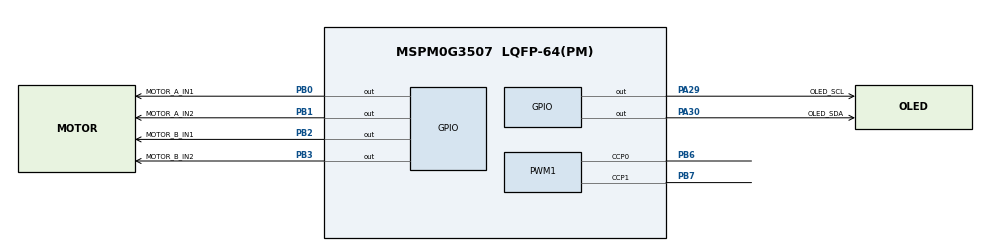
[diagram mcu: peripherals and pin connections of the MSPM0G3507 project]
/**
 * These arguments were used when this file was generated. They will be automatically applied on subsequent loads
 * via the GUI or CLI. Run CLI with '--help' for additional information on how to override these arguments.
 * @cliArgs --device "MSPM0G350X" --part "Default" --package "LQFP-64(PM)" --product "mspm0_sdk@2.10.00.04"
 * @v2CliArgs --device "MSPM0G3507" --package "LQFP-64(PM)" --product "mspm0_sdk@2.10.00.04"
 * @versions {"tool":"1.26.2+4477"}
 */

/**
 * Import the modules used in this configuration.
 */
const GPIO   = scripting.addModule("/ti/driverlib/GPIO", {}, false);
const GPIO1  = GPIO.addInstance();
const GPIO2  = GPIO.addInstance();
const PWM    = scripting.addModule("/ti/driverlib/PWM", {}, false);
const PWM1   = PWM.addInstance();
const SYSCTL = scripting.addModule("/ti/driverlib/SYSCTL");

/**
 * Write custom configuration values to the imported modules.
 */
const divider9       = system.clockTree["UDIV"];
divider9.divideValue = 2;

const multiplier2         = system.clockTree["PLL_QDIV"];
multiplier2.multiplyValue = 4;

const mux4       = system.clockTree["EXHFMUX"];
mux4.inputSelect = "EXHFMUX_XTAL";

const mux8       = system.clockTree["HSCLKMUX"];
mux8.inputSelect = "HSCLKMUX_SYSPLL0";

const mux12       = system.clockTree["SYSPLLMUX"];
mux12.inputSelect = "zSYSPLLMUX_HFCLK";

const pinFunction4       = system.clockTree["HFXT"];
pinFunction4.inputFreq   = 40;
pinFunction4.enable      = true;
pinFunction4.HFXTStartup = 128;

GPIO1.$name                         = "OLED";
GPIO1.associatedPins.create(2);
GPIO1.associatedPins[0].$name       = "OLED_SCL";
GPIO1.associatedPins[0].pin.$assign = "PA29";
GPIO1.associatedPins[1].$name       = "OLED_SDA";
GPIO1.associatedPins[1].pin.$assign = "PA30";

const Board = scripting.addModule("/ti/driverlib/Board", {}, false);

GPIO2.$name                         = "MOTOR_DIR";
GPIO2.associatedPins.create(4);
GPIO2.associatedPins[0].$name       = "MOTOR_A_IN1";
GPIO2.associatedPins[0].pin.$assign = "PB0";
GPIO2.associatedPins[1].$name       = "MOTOR_A_IN2";
GPIO2.associatedPins[1].pin.$assign = "PB1";
GPIO2.associatedPins[2].$name       = "MOTOR_B_IN1";
GPIO2.associatedPins[2].pin.$assign = "PB2";
GPIO2.associatedPins[3].$name       = "MOTOR_B_IN2";
GPIO2.associatedPins[3].pin.$assign = "PB3";

PWM1.$name                      = "PWM_0";
PWM1.timerCount                 = 4000;
PWM1.PWM_CHANNEL_0.$name        = "ti_driverlib_pwm_PWMTimerCC0";
PWM1.ccp0PinConfig.$name        = "ti_driverlib_gpio_GPIOPinGeneric0";
PWM1.peripheral.ccp0Pin.$assign = "PB6";
PWM1.peripheral.ccp1Pin.$assign = "PB7";
PWM1.PWM_CHANNEL_1.$name        = "ti_driverlib_pwm_PWMTimerCC1";
PWM1.ccp1PinConfig.$name        = "ti_driverlib_gpio_GPIOPinGeneric1";

SYSCTL.forceDefaultClkConfig = true;
SYSCTL.clockTreeEn           = true;

/**
 * Pinmux solution for unlocked pins/peripherals. This ensures that minor changes to the automatic solver in a future
 * version of the tool will not impact the pinmux you originally saw.  These lines can be completely deleted in order to
 * re-solve from scratch.
 */
pinFunction4.peripheral.$suggestSolution           = "SYSCTL";
pinFunction4.peripheral.hfxInPin.$suggestSolution  = "PA5";
pinFunction4.peripheral.hfxOutPin.$suggestSolution = "PA6";
Board.peripheral.$suggestSolution                  = "DEBUGSS";
Board.peripheral.swclkPin.$suggestSolution         = "PA20";
Board.peripheral.swdioPin.$suggestSolution         = "PA19";
PWM1.peripheral.$suggestSolution                   = "TIMG6";
